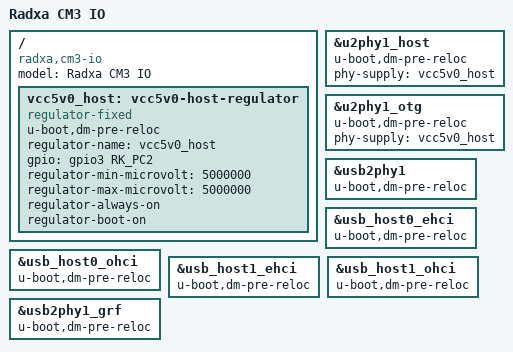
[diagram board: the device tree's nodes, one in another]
// SPDX-License-Identifier: (GPL-2.0+ OR MIT)
/*
 * Copyright (c) 2020 Rockchip Electronics Co., Ltd.
 * Copyright (c) 2021 Radxa Limited.
 *
 */

/dts-v1/;

#include "rk3566-radxa-rock-3-compute-module.dtsi"

/ {
	model = "Radxa CM3 IO";
	compatible = "radxa,cm3-io", "rockchip,rk3566";

	vcc5v0_host: vcc5v0-host-regulator {
		u-boot,dm-pre-reloc;
		compatible = "regulator-fixed";
		regulator-name = "vcc5v0_host";
		gpio = <&gpio3 RK_PC2 GPIO_ACTIVE_HIGH>;
		regulator-min-microvolt = <5000000>;
		regulator-max-microvolt = <5000000>;
		regulator-always-on;
		regulator-boot-on;
	};
};

&u2phy1_host {
	u-boot,dm-pre-reloc;
	phy-supply = <&vcc5v0_host>;
	status = "okay";
};

&u2phy1_otg {
	u-boot,dm-pre-reloc;
	phy-supply = <&vcc5v0_host>;
	status = "okay";
};

&usb2phy1 {
	u-boot,dm-pre-reloc;
	status = "okay";
};

&usb_host0_ehci {
	u-boot,dm-pre-reloc;
	status = "okay";
};

&usb_host0_ohci {
	u-boot,dm-pre-reloc;
	status = "okay";
};

&usb_host1_ehci {
	u-boot,dm-pre-reloc;
	status = "okay";
};

&usb_host1_ohci {
	u-boot,dm-pre-reloc;
	status = "okay";
};

&usb2phy1_grf {
	u-boot,dm-pre-reloc;
};
